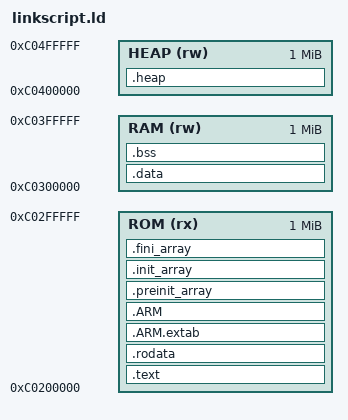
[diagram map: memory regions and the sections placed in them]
OUTPUT_FORMAT("elf32-littlearm", "elf32-littlearm", "elf32-littlearm")
OUTPUT_ARCH(arm)
ENTRY(_Reset)

MEMORY
{
    ROM (rx) :  ORIGIN = 0xC0200000, LENGTH = 0x00100000 
    RAM (rw) :  ORIGIN = 0xC0300000, LENGTH = 0x00100000 
	HEAP (rw) : ORIGIN = 0xC0400000, LENGTH = 0x00100000 
}

__HEAP_SIZE = LENGTH(HEAP);

SECTIONS
{
    .text : {
        *(.vector_table)
		*(.resethandler)
		*(.irqhandler)
		*(.text)
        *(.text*)

					/* Todo: check if we need the next 3 lines */
		*(.glue_7)         /* glue arm to thumb code */
		*(.glue_7t)        /* glue thumb to arm code */
		*(.eh_frame)

		KEEP (*(.init)) /* libc ctors */
		KEEP (*(.fini)) /* libc dtors */

        . = ALIGN(8);
     } > ROM

	/* .rodata sections (constants, strings, etc.) */
	.rodata :
	{
		. = ALIGN(8);
		*(.rodata)         
		*(.rodata*) 
		. = ALIGN(8);
	} > ROM

	/* used for unwinding (probably not used, but is ignored if your app doens't use exceptions */
	.ARM.extab	 : { *(.ARM.extab* .gnu.linkonce.armextab.*) } >ROM
	.ARM : {
		__exidx_start = .;
		*(.ARM.exidx*)
		__exidx_end = .;
	} >ROM

	.preinit_array :
	{
		. = ALIGN(8);
		PROVIDE_HIDDEN (__preinit_array_start = .);
		KEEP (*(.preinit_array*))
		PROVIDE_HIDDEN (__preinit_array_end = .);
		. = ALIGN(8);
	} > ROM

	.init_array :
	{
		. = ALIGN(8);
		PROVIDE_HIDDEN (__init_array_start = .);
		KEEP (*(SORT(.init_array.*)))
		KEEP (*(.init_array*))
		PROVIDE_HIDDEN (__init_array_end = .);
		. = ALIGN(8);
	} > ROM

	.fini_array :
	{
		. = ALIGN(8);
		PROVIDE_HIDDEN (__fini_array_start = .);
		KEEP (*(SORT(.fini_array.*)))
		KEEP (*(.fini_array*))
		PROVIDE_HIDDEN (__fini_array_end = .);
		. = ALIGN(8);
	} > ROM


    _text_end = .;

    .data : AT(_text_end)
    {
        . = ALIGN(8);
        _data_start = .;
        *(.data)
        *(.data*)
        . = ALIGN(8);
        _data_end = .;
    } > RAM

    .bss : {
        . = ALIGN(8);
        _bss_start = .;
        *(.bss)
        *(.bss*)   /* required for some malloc calls */
		*(COMMON)  /* required for libc, such as __lock___atexit_recursive_mutex */
        . = ALIGN(8);
        _bss_end = .;
		. = ALIGN(256);
		_ram_aligned_end = .;
    } > RAM

	.heap (NOLOAD):
	{
		. = ALIGN(8);
		_sheap = .;
		. += __HEAP_SIZE;
		_eheap = .;
	} > HEAP
	end = _sheap;

    _user_stack_start = _ram_aligned_end; 
    _user_stack_end = _user_stack_start + 0x10000;

    _svc_stack_start = _user_stack_end;
    _svc_stack_end = _svc_stack_start + 0x1000;

    _irq_stack_start = _svc_stack_end;
    _irq_stack_end = _irq_stack_start + 0x1000; 

    _fiq_stack_start = _irq_stack_end;
    _fiq_stack_end = _fiq_stack_start + 0x1000;


  /* Remove information from the compiler libraries */
  /DISCARD/ :
  {
    libc.a ( * )
    libm.a ( * )
    libgcc.a ( * )
  }

	.ARM.attributes 0 : { *(.ARM.attributes) }
}
